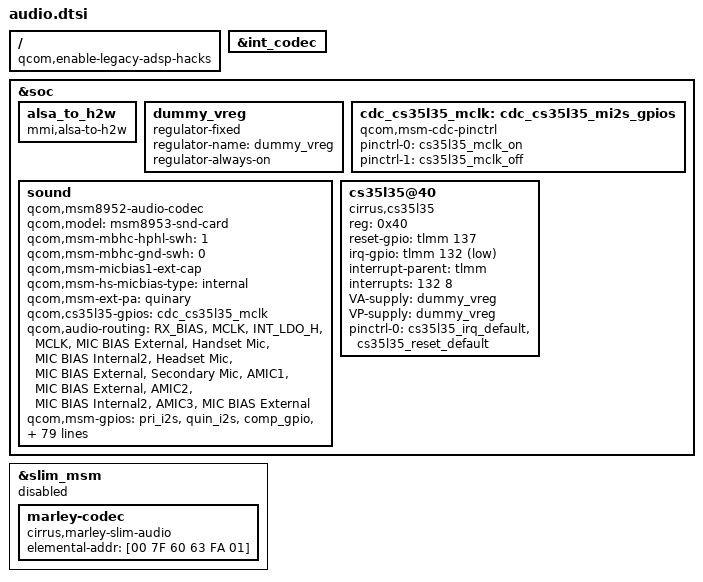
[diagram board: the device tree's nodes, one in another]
/ {
	qcom,enable-legacy-adsp-hacks;
};

/*These nodes are not used and cause pin conflicts*/
/delete-node/ &wsa881x_i2c_45;
/delete-node/ &wsa881x_i2c_f;
/delete-node/ &wsa881x_analog_clk_gpio;
/delete-node/ &wsa881x_analog_reset_gpio;

&int_codec {
	/delete-property/ qcom,cdc-us-eu-gpios;
};

&soc {
	alsa_to_h2w {
		compatible = "mmi,alsa-to-h2w";
	};

	/delete-node/ sound-9335;
	/delete-node/ wsa881x_analog_vi_gpio;
	/delete-node/ msm_cdc_pinctrl_us_euro_sw;

	dummy_vreg: dummy_vreg {
		compatible = "regulator-fixed";
		status = "ok";
		regulator-name = "dummy_vreg";
		regulator-always-on;
	};

	cdc_cs35l35_mclk: cdc_cs35l35_mi2s_gpios {
		compatible = "qcom,msm-cdc-pinctrl";
		pinctrl-names = "aud_active", "aud_sleep";
		pinctrl-0 = <&cs35l35_mclk_on>;
		pinctrl-1 = <&cs35l35_mclk_off>;
	};

	sound {
		status = "okay";
		compatible = "qcom,msm8952-audio-codec";
		qcom,model = "msm8953-snd-card";
		qcom,msm-mbhc-hphl-swh = <1>;
		qcom,msm-mbhc-gnd-swh = <0>;
		qcom,msm-micbias1-ext-cap;
		qcom,msm-hs-micbias-type = "internal";
		qcom,msm-ext-pa = "quinary";
		qcom,cs35l35-gpios = <&cdc_cs35l35_mclk>;
		qcom,audio-routing =
			"RX_BIAS", "MCLK",
			"INT_LDO_H", "MCLK",
			"MIC BIAS External", "Handset Mic",
			"MIC BIAS Internal2", "Headset Mic",
			"MIC BIAS External", "Secondary Mic",
			"AMIC1", "MIC BIAS External",
			"AMIC2", "MIC BIAS Internal2",
			"AMIC3", "MIC BIAS External";
		/delete-property/ qcom,cdc-us-euro-gpios;
		/delete-property/ qcom,hdmi-dba-codec-rx;
		/delete-property/ asoc-wsa-codec-names;
		/delete-property/ asoc-wsa-codec-prefixes;

		/delete-property/ msm-vdd-wsa-switch-supply;
		/delete-property/ qcom,msm-vdd-wsa-switch-voltage;
		/delete-property/ qcom,msm-vdd-wsa-switch-current;
		qcom,msm-gpios =
			"pri_i2s",
			"quin_i2s",
			"comp_gpio",
			"cs35l35_mclk";

		qcom,pinctrl-names =
			"all_off",
			"pri_i2s_act",
			"quin_act",
			"quin_pri_i2s_act",
			"comp_gpio_act",
			"comp_gpio_pri_i2s_act",
			"comp_gpio_quin_act",
			"comp_gpio_quin_pri_i2s_act",
			"cs35l35_mclk_act",
			"cs35l35_mclk_pri_i2s_act",
			"cs35l35_mclk_quin_act",
			"cs35l35_mclk_quin_pri_i2s_act",
			"cs35l35_mclk_comp_gpio_act",
			"cs35l35_mclk_comp_gpio_pri_i2s_act",
			"cs35l35_mclk_comp_gpio_quin_act",
			"all_act";

		pinctrl-0 = <&cdc_pdm_lines_sus &cdc_pdm_comp_lines_sus
			&cdc_pdm_lines_2_sus &pri_tlmm_lines_sus
			&pri_tlmm_ws_sus &cs35l35_mclk_off>;
		pinctrl-1 = <&cdc_pdm_lines_act &cdc_pdm_comp_lines_sus
			&cdc_pdm_lines_2_act &pri_tlmm_lines_sus
			&pri_tlmm_ws_sus &cs35l35_mclk_off>;
		pinctrl-2 = <&cdc_pdm_lines_sus &cdc_pdm_comp_lines_sus
			&cdc_pdm_lines_2_sus &pri_tlmm_lines_act
			&pri_tlmm_ws_act &cs35l35_mclk_off>;
		pinctrl-3 = <&cdc_pdm_lines_act &cdc_pdm_comp_lines_sus
			&cdc_pdm_lines_2_act &pri_tlmm_lines_act
			&pri_tlmm_ws_act &cs35l35_mclk_off>;
		pinctrl-4 = <&cdc_pdm_lines_sus &cdc_pdm_comp_lines_act
			&cdc_pdm_lines_2_sus &pri_tlmm_lines_sus
			&pri_tlmm_ws_sus &cs35l35_mclk_off>;
		pinctrl-5 = <&cdc_pdm_lines_act &cdc_pdm_comp_lines_act
			&cdc_pdm_lines_2_act &pri_tlmm_lines_sus
			&pri_tlmm_ws_sus &cs35l35_mclk_off>;
		pinctrl-6 = <&cdc_pdm_lines_sus &cdc_pdm_comp_lines_act
			&cdc_pdm_lines_2_sus &pri_tlmm_lines_act
			&pri_tlmm_ws_act &cs35l35_mclk_off>;
		pinctrl-7 = <&cdc_pdm_lines_act &cdc_pdm_comp_lines_act
			&cdc_pdm_lines_2_act &pri_tlmm_lines_act
			&pri_tlmm_ws_act &cs35l35_mclk_off>;
		pinctrl-8 = <&cdc_pdm_lines_sus &cdc_pdm_comp_lines_sus
			&cdc_pdm_lines_2_sus &pri_tlmm_lines_sus
			&pri_tlmm_ws_sus &cs35l35_mclk_on>;
		pinctrl-9 = <&cdc_pdm_lines_act &cdc_pdm_comp_lines_sus
			&cdc_pdm_lines_2_act &pri_tlmm_lines_sus
			&pri_tlmm_ws_sus &cs35l35_mclk_on>;
		pinctrl-10 = <&cdc_pdm_lines_sus &cdc_pdm_comp_lines_sus
			&cdc_pdm_lines_2_sus &pri_tlmm_lines_act
			&pri_tlmm_ws_act &cs35l35_mclk_on>;
		pinctrl-11 = <&cdc_pdm_lines_act &cdc_pdm_comp_lines_sus
			&cdc_pdm_lines_2_act &pri_tlmm_lines_act
			&pri_tlmm_ws_act &cs35l35_mclk_on>;
		pinctrl-12 = <&cdc_pdm_lines_sus &cdc_pdm_comp_lines_act
			&cdc_pdm_lines_2_sus &pri_tlmm_lines_sus
			&pri_tlmm_ws_sus &cs35l35_mclk_on>;
		pinctrl-13 = <&cdc_pdm_lines_act &cdc_pdm_comp_lines_act
			&cdc_pdm_lines_2_act &pri_tlmm_lines_sus
			&pri_tlmm_ws_sus &cs35l35_mclk_on>;
		pinctrl-14 = <&cdc_pdm_lines_sus &cdc_pdm_comp_lines_act
			&cdc_pdm_lines_2_sus &pri_tlmm_lines_act
			&pri_tlmm_ws_act &cs35l35_mclk_on>;
		pinctrl-15 = <&cdc_pdm_lines_act &cdc_pdm_comp_lines_act
			&cdc_pdm_lines_2_act &pri_tlmm_lines_act
			&pri_tlmm_ws_act &cs35l35_mclk_on>;

		asoc-codec = <&stub_codec>, <&msm_digital_codec>,
				<&pmic_analog_codec>;
		asoc-codec-names = "msm-stub-codec.1", "msm-dig-codec",
					"analog-codec";
	};

		cs35l35@40 {
			compatible = "cirrus,cs35l35";
			reg = <0x40>;
			reset-gpio = <&tlmm 137 0>;
			irq-gpio = <&tlmm 132 1>;
			interrupt-parent = <&tlmm>;
			interrupts = <132 8>;

			VA-supply = <&dummy_vreg>;
			VP-supply = <&dummy_vreg>;
			pinctrl-names = "default";
			pinctrl-0 = <&cs35l35_irq_default &cs35l35_reset_default>;
	};
};

&slim_msm {
	status = "disabled";
	/delete-node/ tasha_codec;
	marley-codec {
		compatible = "cirrus,marley-slim-audio";
		elemental-addr = [00 7F 60 63 FA 01];
	};
};
